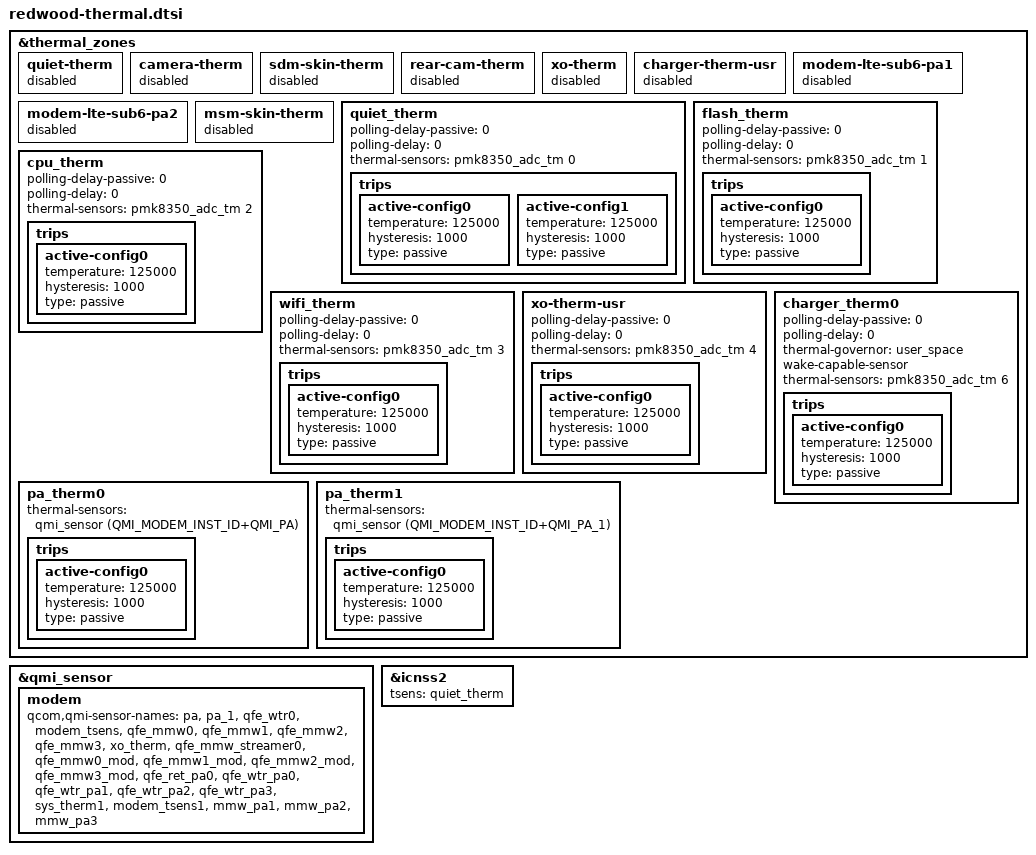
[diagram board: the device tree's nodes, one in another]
// SPDX-License-Identifier: BSD-3-Clause
/*
 * redwood's thermal zones under the names Xiaomi's vendor reads.
 *
 * mi_thermald, the thermal HAL and the charge-only thermal config look the
 * zones up by their 5.4 names: the charge-only virtual sensor reads
 * battery, pa_therm0, quiet_therm, charger_therm0, wifi_therm and
 * cpu_therm. 6.12's PMIC overlay renamed the ADC-TM zones, and a sensor
 * binds only the first enabled zone that points at it, so disable the
 * 6.12 zones and add the vendor names on the same sensors. Based on
 * genie1997's xiaomi-sm7325 thermal zones.
 */

&thermal_zones {
	quiet-therm {
		status = "disabled";
	};

	camera-therm {
		status = "disabled";
	};

	sdm-skin-therm {
		status = "disabled";
	};

	rear-cam-therm {
		status = "disabled";
	};

	xo-therm {
		status = "disabled";
	};

	charger-therm-usr {
		status = "disabled";
	};

	modem-lte-sub6-pa1 {
		status = "disabled";
	};

	modem-lte-sub6-pa2 {
		status = "disabled";
	};

	msm-skin-therm {
		status = "disabled";
	};

	quiet_therm {
		polling-delay-passive = <0>;
		polling-delay = <0>;
		thermal-sensors = <&pmk8350_adc_tm 0>;
		trips {
			active-config0 {
				temperature = <125000>;
				hysteresis = <1000>;
				type = "passive";
			};

			active-config1 {
				temperature = <125000>;
				hysteresis = <1000>;
				type = "passive";
			};
		};
	};

	flash_therm {
		polling-delay-passive = <0>;
		polling-delay = <0>;
		thermal-sensors = <&pmk8350_adc_tm 1>;
		trips {
			active-config0 {
				temperature = <125000>;
				hysteresis = <1000>;
				type = "passive";
			};
		};
	};

	cpu_therm {
		polling-delay-passive = <0>;
		polling-delay = <0>;
		thermal-sensors = <&pmk8350_adc_tm 2>;
		trips {
			active-config0 {
				temperature = <125000>;
				hysteresis = <1000>;
				type = "passive";
			};
		};
	};

	wifi_therm {
		polling-delay-passive = <0>;
		polling-delay = <0>;
		thermal-sensors = <&pmk8350_adc_tm 3>;
		trips {
			active-config0 {
				temperature = <125000>;
				hysteresis = <1000>;
				type = "passive";
			};
		};
	};

	xo-therm-usr {
		polling-delay-passive = <0>;
		polling-delay = <0>;
		thermal-sensors = <&pmk8350_adc_tm 4>;
		trips {
			active-config0 {
				temperature = <125000>;
				hysteresis = <1000>;
				type = "passive";
			};
		};
	};

	/* the charger skin thermistor, PM7325B GPIO2, which is ADC-TM 6 here */
	charger_therm0 {
		polling-delay-passive = <0>;
		polling-delay = <0>;
		thermal-governor = "user_space";
		wake-capable-sensor;
		thermal-sensors = <&pmk8350_adc_tm 6>;
		trips {
			active-config0 {
				temperature = <125000>;
				hysteresis = <1000>;
				type = "passive";
			};
		};
	};

	pa_therm0 {
		thermal-sensors = <&qmi_sensor
				(QMI_MODEM_INST_ID+QMI_PA)>;
		trips {
			active-config0 {
				temperature = <125000>;
				hysteresis = <1000>;
				type = "passive";
			};
		};
	};

	pa_therm1 {
		thermal-sensors = <&qmi_sensor
				(QMI_MODEM_INST_ID+QMI_PA_1)>;
		trips {
			active-config0 {
				temperature = <125000>;
				hysteresis = <1000>;
				type = "passive";
			};
		};
	};
};

/* 6.12's qmi_sensors has no msm_skin_therm, and an unknown name fails its whole probe */
&qmi_sensor {
	modem {
		qcom,qmi-sensor-names = "pa",
					"pa_1",
					"qfe_wtr0",
					"modem_tsens",
					"qfe_mmw0",
					"qfe_mmw1",
					"qfe_mmw2",
					"qfe_mmw3",
					"xo_therm",
					"qfe_mmw_streamer0",
					"qfe_mmw0_mod",
					"qfe_mmw1_mod",
					"qfe_mmw2_mod",
					"qfe_mmw3_mod",
					"qfe_ret_pa0",
					"qfe_wtr_pa0",
					"qfe_wtr_pa1",
					"qfe_wtr_pa2",
					"qfe_wtr_pa3",
					"sys_therm1",
					"modem_tsens1",
					"mmw_pa1",
					"mmw_pa2",
					"mmw_pa3";
	};
};

/* Wi-Fi reads the quiet zone by name for its cold start power-up delay */
&icnss2 {
	tsens = "quiet_therm";
};
